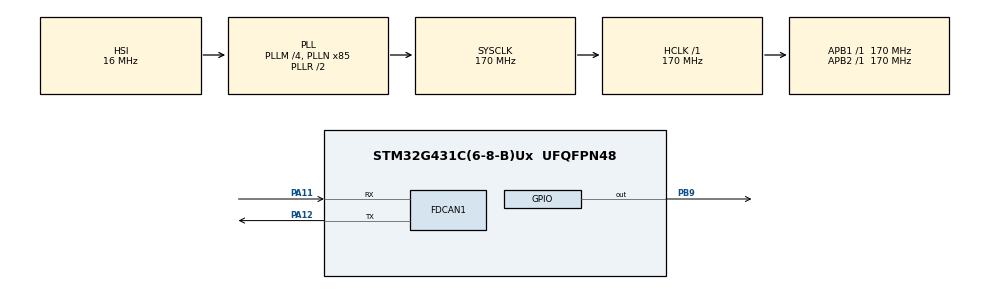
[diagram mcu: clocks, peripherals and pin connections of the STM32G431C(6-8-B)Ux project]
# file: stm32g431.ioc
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FDCAN1.AutoRetransmission=ENABLE
FDCAN1.CalculateBaudRateNominal=999999
FDCAN1.CalculateTimeBitNominal=1000
FDCAN1.CalculateTimeQuantumNominal=58.82352941176471
FDCAN1.ClockDivider=FDCAN_CLOCK_DIV1
FDCAN1.NominalPrescaler=10
FDCAN1.NominalTimeSeg1=12
FDCAN1.NominalTimeSeg2=4
FDCAN1.StdFiltersNbr=1
Mcu.Family=STM32G4
Mcu.Name=STM32G431C(6-8-B)Ux
Mcu.Package=UFQFPN48
NVIC.FDCAN1_IT0_IRQn=true\:0\:0\:false\:false\:true\:true\:true\:true
NVIC.PriorityGroup=NVIC_PRIORITYGROUP_4
PA11.GPIO_Speed=GPIO_SPEED_FREQ_VERY_HIGH
PA11.Mode=FDCAN_Activate
PA11.Signal=FDCAN1_RX
PA12.GPIO_Speed=GPIO_SPEED_FREQ_VERY_HIGH
PA12.Mode=FDCAN_Activate
PA12.Signal=FDCAN1_TX
PA13.Mode=Serial_Wire
PA13.Signal=SYS_JTMS-SWDIO
PA14.Mode=Serial_Wire
PA14.Signal=SYS_JTCK-SWCLK
PB9.Signal=GPIO_Output
ProjectManager.HeapSize=0x200
ProjectManager.StackSize=0x400
ProjectManager.TargetToolchain=MDK-ARM V5.32
RCC.ADC12Freq_Value=170000000
RCC.AHBFreq_Value=170000000
RCC.APB1Freq_Value=170000000
RCC.APB1TimFreq_Value=170000000
RCC.APB2Freq_Value=170000000
RCC.APB2TimFreq_Value=170000000
RCC.CortexFreq_Value=170000000
RCC.EXTERNAL_CLOCK_VALUE=12288000
RCC.HCLKFreq_Value=170000000
RCC.HSE_VALUE=8000000
RCC.HSI48_VALUE=48000000
RCC.HSI_VALUE=16000000
RCC.I2C1CLockSelection=RCC_I2C1CLKSOURCE_HSI
RCC.LSE_VALUE=32768
RCC.PLLM=RCC_PLLM_DIV4
RCC.PLLN=85
RCC.SYSCLKFreq_VALUE=170000000
RCC.SYSCLKSource=RCC_SYSCLKSOURCE_PLLCLK
RCC.USBFreq_Value=170000000
RCC.VCOOutputFreq_Value=340000000
VP_SYS_VS_DBSignals.Mode=DisableDeadBatterySignals
board=custom

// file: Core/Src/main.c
/* USER CODE BEGIN Header */
/**
  ******************************************************************************
  * @file           : main.c
  * @brief          : Main program body
  ******************************************************************************
  * @attention
  *
  * Copyright (c) 2025 STMicroelectronics.
  * All rights reserved.
  *
  * This software is licensed under terms that can be found in the LICENSE file
  * in the root directory of this software component.
  * If no LICENSE file comes with this software, it is provided AS-IS.
  *
  ******************************************************************************
  */
/* USER CODE END Header */
#include "main.h"
#include "fdcan.h"
#include "gpio.h"

/* USER CODE BEGIN PV */
// 在你的用户文件中（例如 main.c）
void HAL_FDCAN_RxFifo0Callback(FDCAN_HandleTypeDef *hfdcan, uint32_t RxFifo0ITs)
{
    uint8_t RxData[8];
    FDCAN_RxHeaderTypeDef RxHeader;

    // 1. 从FIFO中读取报文
    if (HAL_FDCAN_GetRxMessage(hfdcan, FDCAN_RX_FIFO0, &RxHeader, RxData) == HAL_OK)
    {
        // 2. 处理接收到的数据
        // 例如：判断ID，将数据拷贝到应用缓冲区等
        if (RxHeader.Identifier == 0x122)
        {
            // 处理ID为0x123的报文
        }
    }
    // 注意：通常不需要手动清除中断挂起标志，
    // 因为 HAL_FDCAN_GetRxMessage 函数内部会处理FIFO指针[citation:9]。
}
/* USER CODE END PV */

void SystemClock_Config(void);

int main(void)
{

  /* MCU Configuration--------------------------------------------------------*/

  /* Reset of all peripherals, Initializes the Flash interface and the Systick. */
  HAL_Init();

  /* Configure the system clock */
  SystemClock_Config();

  /* Initialize all configured peripherals */
  MX_GPIO_Init();
  MX_FDCAN1_Init();

  /* Infinite loop */
  /* USER CODE BEGIN WHILE */
  while (1)
  {
    FDCAN_TxHeaderTypeDef TxHeader;
    uint8_t TxData[8] = {0x01, 0x02, 0x03, 0x04, 0x05, 0x06, 0x07, 0x08}; // 发送的数据

    TxHeader.Identifier = 0x123;          // 报文ID (标准ID)
    TxHeader.IdType = FDCAN_STANDARD_ID;  // 标准帧
    TxHeader.TxFrameType = FDCAN_DATA_FRAME; // 数据帧
    TxHeader.DataLength = FDCAN_DLC_BYTES_8; // 数据长度8字节
    TxHeader.ErrorStateIndicator = FDCAN_ESI_ACTIVE;
    TxHeader.BitRateSwitch = FDCAN_BRS_OFF; // 经典CAN模式，关闭比特率切换
    TxHeader.FDFormat = FDCAN_CLASSIC_CAN;  // 经典CAN帧
    TxHeader.TxEventFifoControl = FDCAN_NO_TX_EVENTS;
    TxHeader.MessageMarker = 0;

    // 将报文加入发送FIFO，HAL库会处理后续的发送
    if (HAL_FDCAN_AddMessageToTxFifoQ(&hfdcan1, &TxHeader, TxData) != HAL_OK)
    {
        // 发送错误处理
    }

    /* USER CODE END WHILE */

    /* USER CODE BEGIN 3 */
    HAL_GPIO_TogglePin(GPIOB,GPIO_PIN_9);
    HAL_Delay(100);
  }
  /* USER CODE END 3 */
}

void SystemClock_Config(void)
{
  RCC_OscInitTypeDef RCC_OscInitStruct = {0};
  RCC_ClkInitTypeDef RCC_ClkInitStruct = {0};

  /** Configure the main internal regulator output voltage
  */
  HAL_PWREx_ControlVoltageScaling(PWR_REGULATOR_VOLTAGE_SCALE1_BOOST);

  /** Initializes the RCC Oscillators according to the specified parameters
  * in the RCC_OscInitTypeDef structure.
  */
  RCC_OscInitStruct.OscillatorType = RCC_OSCILLATORTYPE_HSI;
  RCC_OscInitStruct.HSIState = RCC_HSI_ON;
  RCC_OscInitStruct.HSICalibrationValue = RCC_HSICALIBRATION_DEFAULT;
  RCC_OscInitStruct.PLL.PLLState = RCC_PLL_ON;
  RCC_OscInitStruct.PLL.PLLSource = RCC_PLLSOURCE_HSI;
  RCC_OscInitStruct.PLL.PLLM = RCC_PLLM_DIV4;
  RCC_OscInitStruct.PLL.PLLN = 85;
  RCC_OscInitStruct.PLL.PLLP = RCC_PLLP_DIV2;
  RCC_OscInitStruct.PLL.PLLQ = RCC_PLLQ_DIV2;
  RCC_OscInitStruct.PLL.PLLR = RCC_PLLR_DIV2;
  if (HAL_RCC_OscConfig(&RCC_OscInitStruct) != HAL_OK)
  {
    Error_Handler();
  }

  /** Initializes the CPU, AHB and APB buses clocks
  */
  RCC_ClkInitStruct.ClockType = RCC_CLOCKTYPE_HCLK|RCC_CLOCKTYPE_SYSCLK
                              |RCC_CLOCKTYPE_PCLK1|RCC_CLOCKTYPE_PCLK2;
  RCC_ClkInitStruct.SYSCLKSource = RCC_SYSCLKSOURCE_PLLCLK;
  RCC_ClkInitStruct.AHBCLKDivider = RCC_SYSCLK_DIV1;
  RCC_ClkInitStruct.APB1CLKDivider = RCC_HCLK_DIV1;
  RCC_ClkInitStruct.APB2CLKDivider = RCC_HCLK_DIV1;

  if (HAL_RCC_ClockConfig(&RCC_ClkInitStruct, FLASH_LATENCY_4) != HAL_OK)
  {
    Error_Handler();
  }
}

void Error_Handler(void)
{
  __disable_irq();
  while (1)
  {
  }
}
